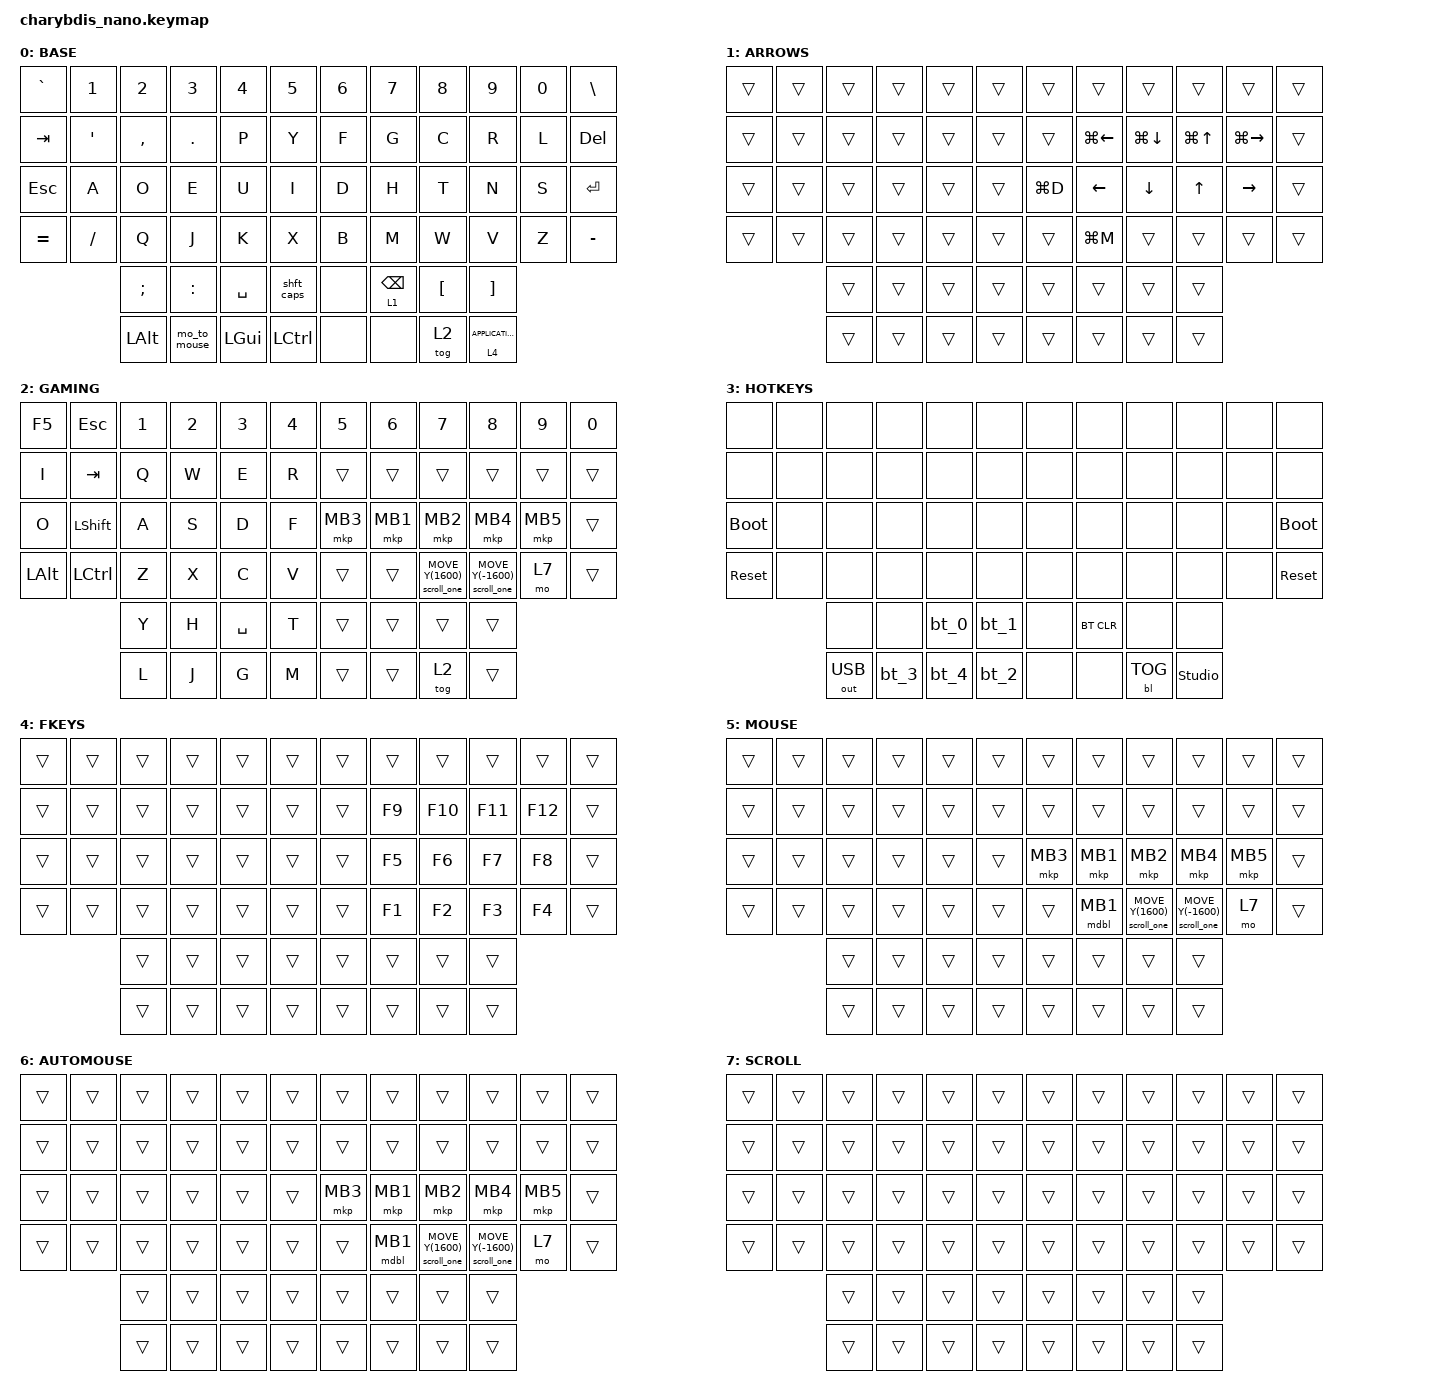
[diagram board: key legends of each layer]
#include <behaviors/mouse_keys.dtsi>
#include <dt-bindings/zmk/mouse.h>
#include <dt-bindings/zmk/runtime_input_processor.h>
#include <dt-bindings/input/input-event-codes.h>
#include <behaviors/runtime-input-processor.dtsi>
#include <behaviors.dtsi>
#include <dt-bindings/zmk/backlight.h>
#include <dt-bindings/zmk/bt.h>
#include <dt-bindings/zmk/keys.h>
#include <dt-bindings/zmk/outputs.h>
#include <dt-bindings/zmk/pointing.h>

&lt {
    tapping-term-ms = <200>;
    flavor = "balanced";
    quick-tap-ms = <170>;
};

&msc {
    trigger-period-ms = <10>;
    delay-ms = <0>;
    time-to-max-speed-ms = <0>;
    acceleration-exponent = <0>;
};

/ {
    behaviors {
        shft_caps: shft_caps {
            compatible = "zmk,behavior-tap-dance";
            label = "SHFT_CAPS";
            #binding-cells = <0>;
            bindings = <&kp LEFT_SHIFT>, <&kp CAPSLOCK>;

            tapping-term-ms = <170>;
        };

        lthr: lthr {
            compatible = "zmk,behavior-hold-tap";
            label = "LTHR";
            bindings = <&mo>, <&kp>;

            #binding-cells = <2>;
            hold-trigger-key-positions = <31 32 33 34 30 43 19 20 21 22>;
            flavor = "hold-preferred";
            tapping-term-ms = <200>;
            quick-tap-ms = <170>;
        };

        mo_to_mouse: mo_to_mouse {
            compatible = "zmk,behavior-tap-dance";
            label = "MO_TO_MOUSE";
            #binding-cells = <0>;
            bindings = <&mo 5>, <&tog 5>;
        };
    };

    combos {
        compatible = "zmk,combos";

        combo_hotkeys {
            bindings = <&mo 3>;
            key-positions = <54 55>;
        };
    };

    macros {
        bt_0: bt_0 {
            compatible = "zmk,behavior-macro";
            #binding-cells = <0>;
            bindings = <&out OUT_BLE &bt BT_SEL 0>;
            label = "BT_0";
        };

        bt_1: bt_1 {
            compatible = "zmk,behavior-macro";
            #binding-cells = <0>;
            bindings = <&out OUT_BLE &bt BT_SEL 1>;
            label = "BT_1";
        };

        bt_2: bt_2 {
            compatible = "zmk,behavior-macro";
            #binding-cells = <0>;
            bindings = <&out OUT_BLE &bt BT_SEL 2>;
            label = "BT_2";
        };

        bt_3: bt_3 {
            compatible = "zmk,behavior-macro";
            #binding-cells = <0>;
            bindings = <&out OUT_BLE &bt BT_SEL 3>;
            label = "BT_3";
        };

        bt_4: bt_4 {
            compatible = "zmk,behavior-macro";
            #binding-cells = <0>;
            bindings = <&out OUT_BLE &bt BT_SEL 4>;
            label = "BT_4";
        };

        gaming: gaming {
            compatible = "zmk,behavior-macro";
            #binding-cells = <0>;
            bindings = <&tog 2 &tog 5>;
            label = "GAMING";
        };

        scroll_one: scroll_one {
            compatible = "zmk,behavior-macro-one-param";
            #binding-cells = <1>;
            bindings =
                <&macro_tap_time 15>,
                <&macro_param_1to1 &msc MACRO_PLACEHOLDER>;

            label = "SCROLL_ONE";
        };

        mdbl: mdbl {
            compatible = "zmk,behavior-macro-one-param";
            #binding-cells = <1>;
            bindings =
                <&macro_tap_time 50>,
                <&macro_param_1to1 &mkp MACRO_PLACEHOLDER>,
                <&macro_tap_time 50>,
                <&macro_wait_time 30>,
                <&macro_param_1to1 &mkp MACRO_PLACEHOLDER>;

            label = "MDBL";
        };
    };

    keymap {
        compatible = "zmk,keymap";

        base {
            label = "BASE";
            bindings = <
&kp GRAVE  &kp N1    &kp N2         &kp N3        &kp N4        &kp N5      &kp N6  &kp N7             &kp N8            &kp N9               &kp N0  &kp BSLH
&kp TAB    &kp SQT   &kp COMMA      &kp DOT       &kp P         &kp Y       &kp F   &kp G              &kp C             &kp R                &kp L   &kp DELETE
&kp ESC    &kp A     &kp O          &kp E         &kp U         &kp I       &kp D   &kp H              &kp T             &kp N                &kp S   &kp RET
&kp EQUAL  &kp FSLH  &kp Q          &kp J         &kp K         &kp X       &kp B   &kp M              &kp W             &kp V                &kp Z   &kp MINUS
                     &kp SEMICOLON  &kp COLON     &kp SPACE     &shft_caps  &none   &lthr 1 BACKSPACE  &kp LEFT_BRACKET  &kp RBKT
                     &kp LEFT_ALT   &mo_to_mouse  &kp LEFT_GUI  &kp LCTRL   &none   &none              &tog 2            &lt 4 K_APPLICATION
            >;
        };

        arrows {
            bindings = <
&trans  &trans  &trans  &trans  &trans  &trans  &trans     &trans        &trans        &trans      &trans         &trans
&trans  &trans  &trans  &trans  &trans  &trans  &trans     &kp LG(LEFT)  &kp LG(DOWN)  &kp LG(UP)  &kp LG(RIGHT)  &trans
&trans  &trans  &trans  &trans  &trans  &trans  &kp LG(D)  &kp LEFT      &kp DOWN      &kp UP      &kp RIGHT      &trans
&trans  &trans  &trans  &trans  &trans  &trans  &trans     &kp LG(M)     &trans        &trans      &trans         &trans
                &trans  &trans  &trans  &trans  &trans     &trans        &trans        &trans
                &trans  &trans  &trans  &trans  &trans     &trans        &trans        &trans
            >;

            label = "ARROWS";
        };

        gaming {
            bindings = <
&kp F5    &kp ESC    &kp N1  &kp N2  &kp N3     &kp N4  &kp N5    &kp N6    &kp N7                    &kp N8                     &kp N9    &kp N0
&kp I     &kp TAB    &kp Q   &kp W   &kp E      &kp R   &trans    &trans    &trans                    &trans                     &trans    &trans
&kp O     &kp LSHFT  &kp A   &kp S   &kp D      &kp F   &mkp MB3  &mkp MB1  &mkp MB2                  &mkp MB4                   &mkp MB5  &trans
&kp LALT  &kp LCTRL  &kp Z   &kp X   &kp C      &kp V   &trans    &trans    &scroll_one MOVE_Y(1600)  &scroll_one MOVE_Y(-1600)  &mo 7     &trans
                     &kp Y   &kp H   &kp SPACE  &kp T   &trans    &trans    &trans                    &trans
                     &kp L   &kp J   &kp G      &kp M   &trans    &trans    &tog 2                    &trans
            >;

            label = "GAMING";
        };

        hotkeys {
            label = "HOTKEYS";
            bindings = <
&none        &none  &none         &none  &none  &none  &none  &none       &none       &none           &none  &none
&none        &none  &none         &none  &none  &none  &none  &none       &none       &none           &none  &none
&bootloader  &none  &none         &none  &none  &none  &none  &none       &none       &none           &none  &bootloader
&sys_reset   &none  &none         &none  &none  &none  &none  &none       &none       &none           &none  &sys_reset
                    &none         &none  &bt_0  &bt_1  &none  &bt BT_CLR  &none       &none
                    &out OUT_USB  &bt_3  &bt_4  &bt_2  &none  &none       &bl BL_TOG  &studio_unlock
            >;
        };

        fkeys {
            bindings = <
&trans  &trans  &trans  &trans  &trans  &trans  &trans  &trans  &trans   &trans   &trans   &trans
&trans  &trans  &trans  &trans  &trans  &trans  &trans  &kp F9  &kp F10  &kp F11  &kp F12  &trans
&trans  &trans  &trans  &trans  &trans  &trans  &trans  &kp F5  &kp F6   &kp F7   &kp F8   &trans
&trans  &trans  &trans  &trans  &trans  &trans  &trans  &kp F1  &kp F2   &kp F3   &kp F4   &trans
                &trans  &trans  &trans  &trans  &trans  &trans  &trans   &trans
                &trans  &trans  &trans  &trans  &trans  &trans  &trans   &trans
            >;

            label = "FKEYS";
        };

        mouse {
            bindings = <
&trans  &trans  &trans  &trans  &trans  &trans  &trans    &trans     &trans                    &trans                     &trans    &trans
&trans  &trans  &trans  &trans  &trans  &trans  &trans    &trans     &trans                    &trans                     &trans    &trans
&trans  &trans  &trans  &trans  &trans  &trans  &mkp MB3  &mkp MB1   &mkp MB2                  &mkp MB4                   &mkp MB5  &trans
&trans  &trans  &trans  &trans  &trans  &trans  &trans    &mdbl MB1  &scroll_one MOVE_Y(1600)  &scroll_one MOVE_Y(-1600)  &mo 7     &trans
                &trans  &trans  &trans  &trans  &trans    &trans     &trans                    &trans
                &trans  &trans  &trans  &trans  &trans    &trans     &trans                    &trans
            >;

            label = "MOUSE";
        };

        automouse {
            label = "AUTOMOUSE";
            bindings = <
&trans  &trans  &trans  &trans  &trans  &trans  &trans    &trans     &trans                    &trans                     &trans    &trans
&trans  &trans  &trans  &trans  &trans  &trans  &trans    &trans     &trans                    &trans                     &trans    &trans
&trans  &trans  &trans  &trans  &trans  &trans  &mkp MB3  &mkp MB1   &mkp MB2                  &mkp MB4                   &mkp MB5  &trans
&trans  &trans  &trans  &trans  &trans  &trans  &trans    &mdbl MB1  &scroll_one MOVE_Y(1600)  &scroll_one MOVE_Y(-1600)  &mo 7     &trans
                &trans  &trans  &trans  &trans  &trans    &trans     &trans                    &trans
                &trans  &trans  &trans  &trans  &trans    &trans     &trans                    &trans
            >;
        };

        scroll {
            bindings = <
&trans  &trans  &trans  &trans  &trans  &trans  &trans  &trans  &trans  &trans  &trans  &trans
&trans  &trans  &trans  &trans  &trans  &trans  &trans  &trans  &trans  &trans  &trans  &trans
&trans  &trans  &trans  &trans  &trans  &trans  &trans  &trans  &trans  &trans  &trans  &trans
&trans  &trans  &trans  &trans  &trans  &trans  &trans  &trans  &trans  &trans  &trans  &trans
                &trans  &trans  &trans  &trans  &trans  &trans  &trans  &trans
                &trans  &trans  &trans  &trans  &trans  &trans  &trans  &trans
            >;

            label = "SCROLL";
        };
    };

    conditional_layers { compatible = "zmk,conditional-layers"; };
};

&mouse_runtime_input_processor {
    temp-layer-enabled;
    temp-layer = <6>;
    temp-layer-activation-delay-ms = <50>;
    temp-layer-deactivation-delay-ms = <400>;
};

&scroll_runtime_input_processor {
    active-layers = <BIT(7)>;
    x-codes = <INPUT_REL_X>;
    y-codes = <INPUT_REL_Y>;
    xy-to-scroll-enabled;
    axis-snap-threshold = <100>;
};
